# MSPM0G121X register map
Vendor: Texas Instruments; File version: Revised: 2025-10-06 10:58:04
CPU: CM0 r0p1, little endian, MPU, no FPU, 3 interrupt priority bits
Registers are 32-bit, read-write, reset 0x0 unless marked. A register's access mark holds for its fields unless they carry their own. Offsets are from the block's base; [hi:lo] are bit positions; lines under a group give offsets from that group; {n}, {i} and the like mark numbered series; 'fields as' and 'values as' point back to an identical list.

## TIMG8 — PERIPHERALREGION
Base 0x40090000
0x400 TIMG8_FSUB_0 — Subsciber Port 0
  [3:0] CHANID — 0 = disconnected. 1-15 = connected to channelID = CHANID.
    0=UNCONNECTED (A value of 0 specifies that the event is not connected)
0x404 TIMG8_FSUB_1 — Subscriber Port 1
  fields as TIMG8_FSUB_0
0x444 TIMG8_FPUB_0 — Publisher Port 0
  fields as TIMG8_FSUB_0
0x448 TIMG8_FPUB_1 — Publisher Port 1
  fields as TIMG8_FSUB_0
{0x800+0x18*i} TIMG8_GPRCM[{i}] (i=0..0) group
  0x00 TIMG8_PWREN — Power enable
    [0] ENABLE — Enable the power
      0=DISABLE (Disable Power); 1=ENABLE (Enable Power)
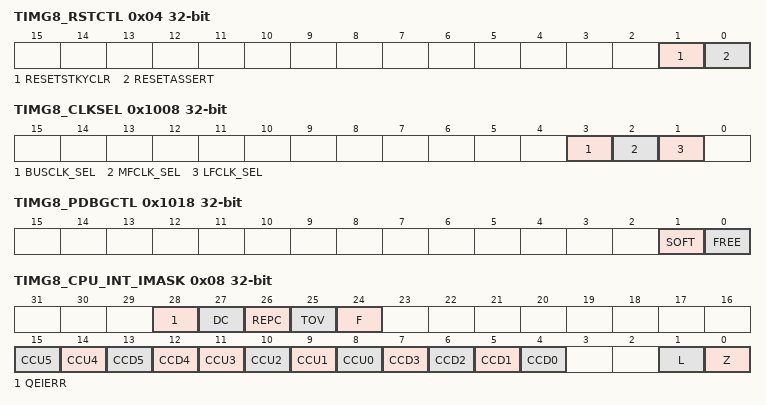
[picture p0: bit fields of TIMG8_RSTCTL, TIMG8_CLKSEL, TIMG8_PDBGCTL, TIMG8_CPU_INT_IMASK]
  0x04 TIMG8_RSTCTL wo — Reset Control
    [1] RESETSTKYCLR — Clear the RESETSTKY bit in the STAT register
      0=NOP (Writing 0 has no effect); 1=CLR (Clear reset sticky bit)
    [0] RESETASSERT — Assert reset to the peripheral
      0=NOP (Writing 0 has no effect); 1=ASSERT (Assert reset)
  0x14 TIMG8_STAT ro — Status Register
    [16] RESETSTKY — This bit indicates, if the peripheral was reset, since this bit was cleared by RESETSTKYCLR in the RSTCTL register
      0=NORES (The peripheral has not been reset since this bit was last cleared by RESETSTKYCLR in the RSTCTL register); 1=RESET (The peripheral was reset since the last bit clear)
0x1000 TIMG8_CLKDIV — Clock Divider
  [2:0] RATIO — Selects divide ratio of module clock
    0=DIV_BY_1 (Do not divide clock source); {v}=DIV_BY_{v+1} (Divide clock source by {v+1}) (v=1..7)
0x1008 TIMG8_CLKSEL — Clock Select for Ultra Low Power peripherals
  [all] fields
    0=DISABLE (Does not select this clock as a source); 1=ENABLE (Select this clock as a source)
  [3] BUSCLK_SEL — Selects BUSCLK as clock source if enabled
  [2] MFCLK_SEL — Selects MFCLK as clock source if enabled
  [1] LFCLK_SEL — Selects LFCLK as clock source if enabled
0x1018 TIMG8_PDBGCTL — Peripheral Debug Control
  [1] SOFT — Soft halt boundary control. This function is only available, if [FREE] is set to 'STOP'
    0=IMMEDIATE (The peripheral will halt immediately, even if the resultant state will result in corruption if the system is restarted); 1=DELAYED (The peripheral blocks the debug freeze until it has reached a boundary where it can resume without corruption)
  [0] FREE — Free run control
    0=STOP (The peripheral freezes functionality while the Core Halted input is asserted and resumes when it is deasserted.); 1=RUN (The peripheral ignores the state of the Core Halted input)
{0x1020+0x2C*i} TIMG8_CPU_INT[{i}] (i=0..0) group
  0x00 TIMG8_CPU_INT_IIDX ro — Interrupt index
    [7:0] STAT — Interrupt index status
      0=NO_INTR (No interrupt pending); 1=Z (Interrupt Source: Zero event (Z)); 2=L (nterrupt Source: Load event (L)); {v}=CCD{v-5} (Interrupt Source: Capture or compare down event (CCD{v-5})) (v=5..8); {v}=CCU{v-9} (Interrupt Source: Capture or compare up event (CCU{v-9})) (v=9..12); 13=CCD4 (Interrupt Source: Compare down event (CCD4)); 14=CCD5 (Interrupt Source: Compare down event (CCD5)); 15=CCU4 (Interrupt Source: Compare down event (CCU4)); 16=CCU5 (Interrupt Source: Compare down event (CCU5)); 25=F (Interrupt Source: Fault Event generated an interrupt. (F)); 26=TOV (Interrupt Source: Trigger overflow (TOV)); 27=REPC (Interrupt Source: Repeat Counter Zero (REPC)); 28=DC (Interrupt Source: Direction Change (DC)); 29=QEIERR (Interrupt Source:QEI Incorrect state transition error (QEIERR))
  0x08 TIMG8_CPU_INT_IMASK — Interrupt mask
    [28] QEIERR — QEIERR Event mask
      0=CLR (Disable Event); 1=SET (Enable Event)
    [27] DC — Direction Change Event mask
      0=CLR (Disable Event); 1=SET (Enable Event)
    [26] REPC — Repeat Counter Zero Event mask
      0=CLR (Disable Event); 1=SET (Enable Event)
    [25] TOV — Trigger Overflow Event mask
      0=CLR (Disable Event); 1=SET (Enable Event)
    [24] F — Fault Event mask
      0=CLR (Disable Event); 1=SET (Enable Event)
    [15] CCU5 — Compare UP event mask CCP5
      0=CLR (Clear Interrupt Mask); 1=SET (Set Interrupt Mask)
    [14] CCU4 — Compare UP event mask CCP4
      0=CLR (Clear Interrupt Mask); 1=SET (Set Interrupt Mask)
    [13] CCD5 — Compare DN event mask CCP5
      0=CLR (Clear Interrupt Mask); 1=SET (Set Interrupt Mask)
    [12] CCD4 — Compare DN event mask CCP4
      0=CLR (Clear Interrupt Mask); 1=SET (Set Interrupt Mask)
    [n+8] CCU{n} (n=0..3) — Capture or Compare UP event mask CCP{n}
      0=CLR (Clear Interrupt Mask); 1=SET (Set Interrupt Mask)
    [n+4] CCD{n} (n=0..3) — Capture or Compare DN event mask CCP{n}
      0=CLR (Clear Interrupt Mask); 1=SET (Set Interrupt Mask)
    [1] L — Load Event mask
      0=CLR (Clear Interrupt Mask); 1=SET (Set Interrupt Mask)
    [0] Z — Zero Event mask
      0=CLR (Disable Event); 1=SET (Enable Event)
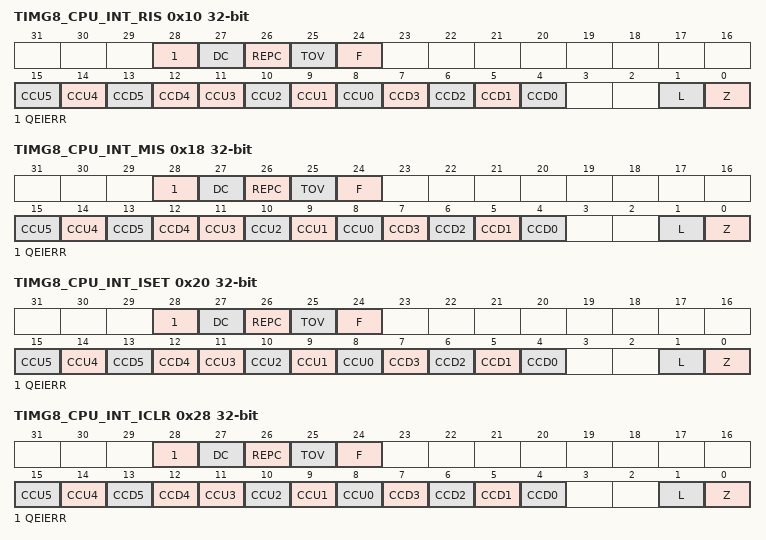
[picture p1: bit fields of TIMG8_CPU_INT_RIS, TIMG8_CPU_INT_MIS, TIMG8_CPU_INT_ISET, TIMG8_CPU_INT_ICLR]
  0x10 TIMG8_CPU_INT_RIS ro — Raw interrupt status
    [all] fields
      0=CLR (Event Cleared); 1=SET (Event Set)
    [28] QEIERR — QEIERR, set on an incorrect state transition on the encoder interface.
    [27] DC — Direction Change
    [26] REPC — Repeat Counter Zero
    [25] TOV — Trigger overflow
    [24] F — Fault
    [15] CCU5 — Compare up event generated an interrupt CCP5
    [14] CCU4 — Compare up event generated an interrupt CCU4
    [13] CCD5 — Compare down event generated an interrupt CCD5
    [12] CCD4 — Compare down event generated an interrupt CCD4
    [n+8] CCU{n} (n=0..3) — Capture or compare up event generated an interrupt CCP{n}
    [n+4] CCD{n} (n=0..3) — Capture or compare down event generated an interrupt CCP{n}
    [1] L — Load event generated an interrupt.
    [0] Z — Zero event generated an interrupt.
  0x18 TIMG8_CPU_INT_MIS ro — Masked interrupt status
    [all] fields
      0=CLR (Event Cleared); 1=SET (Event Set)
    [28] QEIERR
    [27] DC — Direction Change
    [26] REPC — Repeat Counter Zero
    [25] TOV — Trigger overflow
    [24] F — Fault
    [15] CCU5 — Compare up event generated an interrupt CCP5
    [14] CCU4 — Compare up event generated an interrupt CCP4
    [13] CCD5 — Compare down event generated an interrupt CCP5
    [12] CCD4 — Compare down event generated an interrupt CCP4
    [n+8] CCU{n} (n=0..3) — Capture or compare up event generated an interrupt CCP{n}
    [n+4] CCD{n} (n=0..3) — Capture or compare down event generated an interrupt CCP{n}
    [1] L — Load event generated an interrupt.
    [0] Z — Zero event generated an interrupt.
  0x20 TIMG8_CPU_INT_ISET wo — Interrupt set
    [all] fields
      0=NO_EFFECT (Writing 0 has no effect.); 1=SET (Event Set)
    [28] QEIERR — QEIERR event SET
    [27] DC — Direction Change event SET
    [26] REPC — Repeat Counter Zero event SET
    [25] TOV — Trigger Overflow event SET
    [24] F — Fault event SET
    [15] CCU5 — Compare up event 5 SET
    [14] CCU4 — Compare up event 4 SET
    [13] CCD5 — Compare down event 5 SET
    [12] CCD4 — Compare down event 4 SET
    [n+8] CCU{n} (n=0..3) — Capture or compare up event SET
    [n+4] CCD{n} (n=0..3) — Capture or compare down event SET
    [1] L — Load event SET
    [0] Z — Zero event SET
  0x28 TIMG8_CPU_INT_ICLR wo — Interrupt clear
    [all] fields
      0=NO_EFFECT (Writing 0 has no effect.); 1=CLR (Event Clear)
    [28] QEIERR — QEIERR event CLEAR
    [27] DC — Direction Change event CLEAR
    [26] REPC — Repeat Counter Zero event CLEAR
    [25] TOV — Trigger Overflow event CLEAR
    [24] F — Fault event CLEAR
    [15] CCU5 — Compare up event 5 CLEAR
    [14] CCU4 — Compare up event 4 CLEAR
    [13] CCD5 — Compare down event 5 CLEAR
    [12] CCD4 — Compare down event 4 CLEAR
    [n+8] CCU{n} (n=0..3) — Capture or compare up event CLEAR
    [n+4] CCD{n} (n=0..3) — Capture or compare down event CLEAR
    [1] L — Load event CLEAR
    [0] Z — Zero event CLEAR
{0x1050+0x2C*i} TIMG8_GEN_EVENT0[{i}] (i=0..0) group
  0x00 TIMG8_GEN_EVENT0_IIDX ro — Interrupt index
    fields as TIMG8_CPU_INT[0].TIMG8_CPU_INT_IIDX
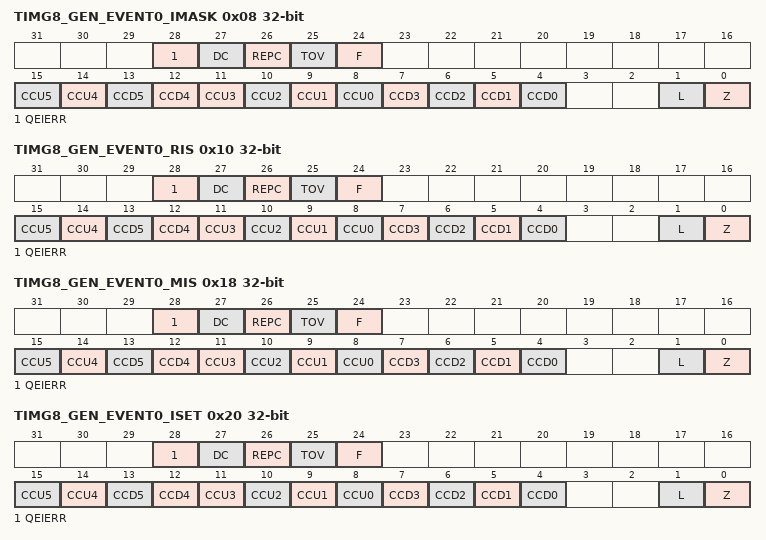
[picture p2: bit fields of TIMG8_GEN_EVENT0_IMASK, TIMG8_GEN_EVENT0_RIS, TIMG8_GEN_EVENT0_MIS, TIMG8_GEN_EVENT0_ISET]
  0x08 TIMG8_GEN_EVENT0_IMASK — Interrupt mask
    fields as TIMG8_CPU_INT[0].TIMG8_CPU_INT_IMASK
  0x10 TIMG8_GEN_EVENT0_RIS ro — Raw interrupt status
    fields as TIMG8_CPU_INT[0].TIMG8_CPU_INT_RIS
  0x18 TIMG8_GEN_EVENT0_MIS ro — Masked interrupt status
    fields as TIMG8_CPU_INT[0].TIMG8_CPU_INT_MIS
  0x20 TIMG8_GEN_EVENT0_ISET wo — Interrupt set
    fields as TIMG8_CPU_INT[0].TIMG8_CPU_INT_ISET
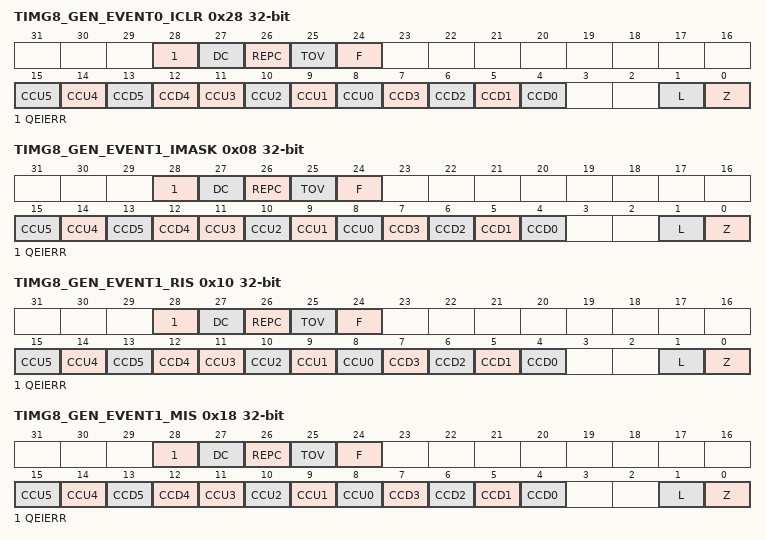
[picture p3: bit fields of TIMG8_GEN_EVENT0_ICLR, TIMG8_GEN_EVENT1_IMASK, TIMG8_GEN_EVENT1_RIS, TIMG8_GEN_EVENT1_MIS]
  0x28 TIMG8_GEN_EVENT0_ICLR wo — Interrupt clear
    fields as TIMG8_CPU_INT[0].TIMG8_CPU_INT_ICLR
{0x1080+0x2C*i} TIMG8_GEN_EVENT1[{i}] (i=0..0) group
  0x00 TIMG8_GEN_EVENT1_IIDX ro — Interrupt index
    fields as TIMG8_CPU_INT[0].TIMG8_CPU_INT_IIDX
  0x08 TIMG8_GEN_EVENT1_IMASK — Interrupt mask
    fields as TIMG8_CPU_INT[0].TIMG8_CPU_INT_IMASK
  0x10 TIMG8_GEN_EVENT1_RIS ro — Raw interrupt status
    fields as TIMG8_CPU_INT[0].TIMG8_CPU_INT_RIS
  0x18 TIMG8_GEN_EVENT1_MIS ro — Masked interrupt status
    fields as TIMG8_CPU_INT[0].TIMG8_CPU_INT_MIS
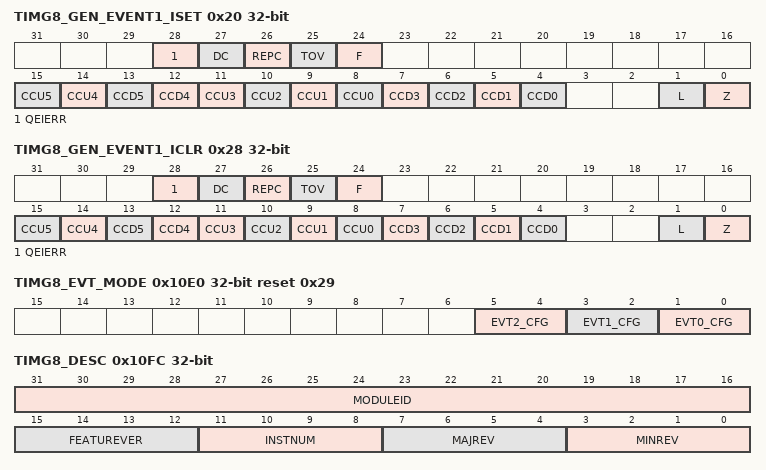
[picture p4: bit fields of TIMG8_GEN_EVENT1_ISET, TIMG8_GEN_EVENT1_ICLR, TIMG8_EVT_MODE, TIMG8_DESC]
  0x20 TIMG8_GEN_EVENT1_ISET wo — Interrupt set
    fields as TIMG8_CPU_INT[0].TIMG8_CPU_INT_ISET
  0x28 TIMG8_GEN_EVENT1_ICLR wo — Interrupt clear
    fields as TIMG8_CPU_INT[0].TIMG8_CPU_INT_ICLR
0x10E0 TIMG8_EVT_MODE reset 0x29 — Event Mode
  [all] fields
    0=DISABLE (The interrupt or event line is disabled.); 1=SOFTWARE (The interrupt or event line is in software mode. Software must clear the RIS.); 2=HARDWARE (The interrupt or event line is in hardware mode. The hardware (another module) clears automatically the associated RIS flag.)
  [5:4] EVT2_CFG ro — Event line mode select for event corresponding to GEN_EVENT1
  [3:2] EVT1_CFG ro — Event line mode select for event corresponding to GEN_EVENT0
  [1:0] EVT0_CFG ro — Event line mode select for event corresponding to CPU_INT
0x10FC TIMG8_DESC ro — Module Description
  [31:16] MODULEID — Module identification contains a unique peripheral identification number. The assignments are maintained in a central database for all of the platform modules to ensure uniqueness.
  [15:12] FEATUREVER — Feature Set for the module *instance*
  [11:8] INSTNUM — Instance Number within the device. This will be a parameter to the RTL for modules that can have multiple instances
  [7:4] MAJREV — Major rev of the IP
  [3:0] MINREV — Minor rev of the IP
{0x1100+0x28*i} TIMG8_COMMONREGS[{i}] (i=0..0) group
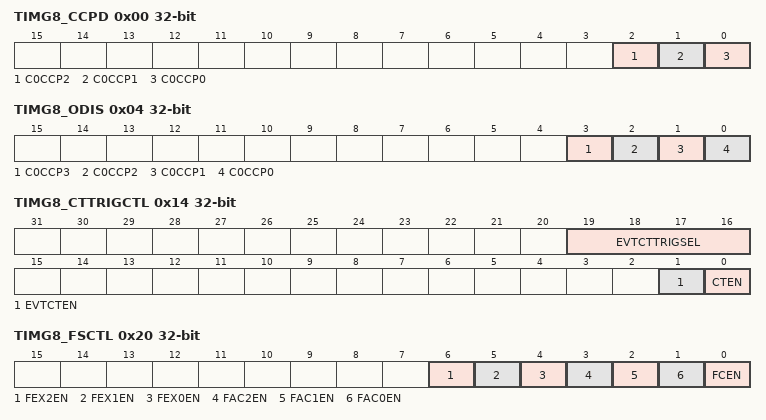
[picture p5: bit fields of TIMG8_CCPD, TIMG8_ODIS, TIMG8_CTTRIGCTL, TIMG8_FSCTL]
  0x00 TIMG8_CCPD — CCP Direction
    [all] fields
      0=INPUT; 1=OUTPUT
    [2] C0CCP2 — CCP2 direction
    [1] C0CCP1 — CCP1 direction
    [0] C0CCP0 — CCP0 direction
  0x04 TIMG8_ODIS — Output Disable
    [3] C0CCP3 — Counter CCP3 Disable Mask Defines whether CCP3 of Counter n is forced low or not
      0=CCP_OUTPUT_OCTL (Output function as selected by the OCTL register CCPO field are provided to occpout[2].); 1=CCP_OUTPUT_LOW (CCP output occpout[3] is forced low.)
    [2] C0CCP2 — Counter CCP2 Disable Mask Defines whether CCP2 of Counter n is forced low or not
      0=CCP_OUTPUT_OCTL (Output function as selected by the OCTL register CCPO field are provided to output inversion block.); 1=CCP_OUTPUT_LOW (CCP output occpout[2] is forced low.)
    [1] C0CCP1 — Counter CCP1 Disable Mask Defines whether CCP0 of Counter n is forced low or not
      0=CCP_OUTPUT_OCTL (Output function as selected by the OCTL register CCPO field are provided to output inversion block.); 1=CCP_OUTPUT_LOW (CCP output occpout[1] is forced low.)
    [0] C0CCP0 — Counter CCP0 Disable Mask Defines whether CCP0 of Counter n is forced low or not
      0=CCP_OUTPUT_OCTL (Output function as selected by the OCTL register CCPO field are provided to output inversion block.); 1=CCP_OUTPUT_LOW (CCP output occpout[0] is forced low.)
  0x08 TIMG8_CCLKCTL — Counter Clock Control Register
    [0] CLKEN — Clock Enable Disables the clock gating to the module. SW has to explicitly program the value to 0 to gate the clock.
      0=DISABLED (Clock is disabled.); 1=ENABLED (Clock is enabled)
  0x0C TIMG8_CPS — Clock Prescale Register
    [7:0] PCNT — Pre-Scale Count This field specifies the pre-scale count value. The selected TIMCLK source is divided by a value of (PCNT+1). A PCNT value of 0 divides TIMCLK by 1, effectively bypassing the divider. A PCNT value of greater than 0 divides the TIMCLK source generating a slower clock
  0x10 TIMG8_CPSV ro — Clock prescale count status register
    [7:0] CPSVAL — Current Prescale Count Value
  0x14 TIMG8_CTTRIGCTL — Timer Cross Trigger Control Register
    [19:16] EVTCTTRIGSEL — Used to Select the subscriber port that should be used for input cross trigger.
      0=FSUB0 (Use FSUB0 as cross trigger source.); 1=FSUB1 (Use FSUB1 as cross trigger source.); 2=Z (Use Zero event as cross trigger source.); 3=L (Use Load event as cross trigger source.); {v}=CCD{v-4} (Use CCD{v-4} event as cross trigger source.) (v=4..7); {v}=CCU{v-8} (Use CCU{v-8} event as cross trigger source.) (v=8..11)
    [1] EVTCTEN — Enable the Input Trigger Conditions to the Timer module as a condition for Cross Triggers.
      0=DISABLED (Cross trigger generation disabled.); 1=ENABLE (Cross trigger generation enabled)
    [0] CTEN — Timer Cross trigger enable. This field is used to enable whether the SW or HW logic can generate a timer cross trigger event in the system. These cross triggers are connected to the respective timer trigger in of the other timer IPs in the SOC power domain. The timer cross trigger is essentially the combined logic of the HW and SW conditions controlling EN bit in the CTRCTL register.
      values as EVTCTEN
  0x1C TIMG8_CTTRIG wo — Timer Cross Trigger Register
    [0] TRIG — Generate Cross Trigger This bit when programmed will generate a synchronized trigger condition all the cross trigger enabled Timer instances including current timer instance.
      0=DISABLED (Cross trigger generation disabled); 1=GENERATE (Generate Cross trigger pulse)
  0x20 TIMG8_FSCTL — Fault Source Control
    [all] fields
      0=DISABLE; 1=ENABLE
    [6] FEX2EN — This field controls whether the fault is caused by external fault pin 2.
    [5] FEX1EN — This field controls whether the fault is caused by external fault pin 1.
    [4] FEX0EN — This field controls whether the fault is caused by external fault pin 0.
    [3] FAC2EN — This field controls whether the fault is caused by COMP2 output.
    [2] FAC1EN — This field controls whether the fault is caused by COMP1 output.
    [1] FAC0EN — This field controls whether the fault signal is caused by COMP0 output.
    [0] FCEN — This field controls whether the fault is caused by the system clock fault.
  0x24 TIMG8_GCTL — Global control register
    [0] SHDWLDEN — Enables shadow to active load of bufferred registers and register fields.
      0=DISABLE; 1=ENABLE
{0x1800+0xD8*i} TIMG8_COUNTERREGS[{i}] (i=0..0) group
  0x00 TIMG8_CTR — Counter Register
    [31:0] CCTR — Current Counter value
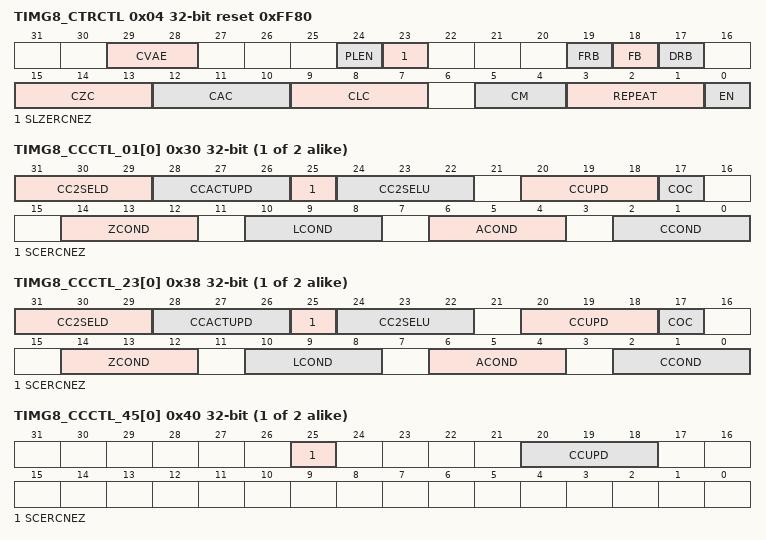
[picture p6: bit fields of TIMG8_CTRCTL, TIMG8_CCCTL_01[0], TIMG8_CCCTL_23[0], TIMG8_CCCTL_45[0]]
  0x04 TIMG8_CTRCTL reset 0xFF80 — Counter Control Register
    [29:28] CVAE — Counter Value After Enable. This field specifies the initialization condition of the counter when the EN bit is changed from 0 to 1 by a write to the CTRCTL register. Note that an external event can also cause the EN bit to go active.
      0=LDVAL (The counter is set to the LOAD register value); 1=NOCHANGE (The counter value is unchanged from its current value which could have been initialized by software); 2=ZEROVAL (The counter is set to zero)
    [24] PLEN — Phase Load Enable. This bit allows the timer to have phase load feature.
      0=DISABLED; 1=ENABLED
    [23] SLZERCNEZ — Suppress Load and Zero Events if Repeat Counter is Not Equal to Zero. This bit suppresses the generation of the Z (zero) and L (load) events from the counter when the repeat counter (RC) value is not 0.
      0=DISABLED (Disabled. Z and L events are always generated from the counter when their conditions are generated.); 1=ENABLED (Enabled. Z and L events are generated from the counter when their conditions are generated and the RC register value is 0.)
    [19] FRB — Fault Resume Behavior This bit specifies what the device does following the release/exit of fault condition.
      0=RESUME (Resume counting); 1=CVAE_ACTION (Perform the action as specified by the CVAE field.)
    [18] FB — Fault Behavior This bit specifies whether the counter continues running or suspends during a fault mode. There is a separate control under REPEAT to indicate whether counting is to suspend at next Counter==0
      0=CONT_COUNT (Continues counting); 1=SUSP_COUNT (Suspends counting)
    [17] DRB — Debug Resume Behavior This bit specifies what the device does following the release/exit of debug mode.
      values as FRB
    [15:13] CZC — Counter Zero Control This field specifies what controls the counter operation with respect to zeroing the counter value. Encodings 1-3 are present based on the CCPC parameter value. Bits 4-5 are present based on the HQEI parameter value. Any encodings not provided are documented as reserved.
      0=CCCTL0_ZCOND; 1=CCCTL1_ZCOND; 2=CCCTL2_ZCOND (CCCTL_2 ZCOND This value exists when there are 4 channels.); 3=CCCTL3_ZCOND (CCCTL_3 ZCOND This value exists when there are 4 channels.); 4=QEI_2INP (Controlled by 2-input QEI mode This value exists when TIMER support QEI feature.); 5=QEI_3INP (Controlled by 3-input QEI mode This value exists when TIMER support QEI feature.)
    [12:10] CAC — Counter Advance Control. This field specifies what controls the counter operation with respect to advancing (incrementing or decrementing) the counter value. Encodings 1-3 are present based on the CCPC parameter value. Bits 4-5 are present based on the HQEI parameter value. Any encodings not provided are documented as reserved.
      0=CCCTL0_ACOND; 1=CCCTL1_ACOND; 2=CCCTL2_ACOND (CCCTL_2 ACOND This value exists when there are 4 channels.); 3=CCCTL3_ACOND (CCCTL_3 ACOND This value exists when there are 4 channels.); 4=QEI_2INP (Controlled by 2-input QEI mode This value exists when TIMER support QEI feature.); 5=QEI_3INP (Controlled by 3-input QEI mode This value exists when TIMER support QEI feature.)
    [9:7] CLC — Counter Load Control. This field specifies what controls the counter operation with respect to setting the counter to the LD register value. Encodings 1-3 are present based on the CCPC parameter value. Bits 4-5 are present based on the HQEI parameter value. Any encodings not provided are documented as reserved.
      0=CCCTL0_LCOND; 1=CCCTL1_LCOND; 2=CCCTL2_LCOND (CCCTL_2 LCOND This value exists when there are 4 channels.); 3=CCCTL3_LCOND (CCCTL_3 LCOND This value exists when there are 4 channels.); 4=QEI_2INP (Controlled by 2 input QEI mode. This value exists when TIMER support QEI feature.); 5=QEI_3INP (Controlled by 3 input QEI mode. This value exists when TIMER support QEI feature.)
    [5:4] CM — Count Mode
      0=DOWN; 1=UP_DOWN; 2=UP (Counter counts up.)
    [3:1] REPEAT — Repeat. The repeat bit controls whether the counter continues to advance following a zero event, or the exiting of a debug or fault condition. If counting down, a zero event is followed by a load at the next advance condition. If counting up-down, a zero event is followed by an advance event (+1). The intent of encoding 3 is that if the debug condition is in effect, the generation of the load pulse is deferred until the debug condition is over. This allows the counter to reach zero before counting is suspended.
      0=Does not automatically advance following a zero event; 1=Continues to advance following a zero event; 3=Continues to advance following a zero event if the debug mode is not in effect, or following the release of the debug mode
    [0] EN — Counter Enable. This bit allows the timer to advance This bit is automatically cleared if REPEAT=0 (do not automatically reload) and the counter value equals zero. CPU Write: A register write that sets the EN bit, the counter value is set per the CVAE value. Hardware: This bit may also be set as the result of an LCOND or ZCOND condition being met and the counter value changed to the load value or zero value, respectively.
      0=DISABLED; 1=ENABLED
  0x08 TIMG8_LOAD — Load Register
    [31:0] LD — Load Value
  {0x10+4j} TIMG8_CC_01[{j}] (j=0..1) — Capture or Compare Register 0/1
    [31:0] CCVAL — Capture or compare value
  {0x18+4j} TIMG8_CC_23[{j}] (j=0..1) — Capture or Compare Register 2/3
    [31:0] CCVAL — Capture or compare value
  {0x20+4j} TIMG8_CC_45[{j}] (j=0..1) — The CC_45 register are a registers which can be used as compare to the current CTR to create an events CC4U, CC4D, CC5U and CC5D.
    [31:0] CCVAL — Capture or compare value
  {0x30+4j} TIMG8_CCCTL_01[{j}] (j=0..1) — Capture or Compare Control Registers 0/1
    [31:29] CC2SELD — Selects the source second CCD event.
      {v}=SEL_CCD{v} (Selects CCD from CC{v}.) (v=0..5)
    [28:26] CCACTUPD — CCACT shadow register Update Method This field controls how updates to the CCACT shadow register are performed
      0=Immediately (Value written to the CCACT register has immediate effect.); 1=Zero_EVT (Following a zero event (CTR=0) Writes to the CCACTx_y register are stored in shadow register and transferred to CCACTx_y in the TIMCLK cycle following CTR equals 0.); 2=Compare_Down_EVT (Following a CCD event (CTR=CC_xy) Writes to the CCACTx_y register are stored in shadow register and transferred to CCACTx_y in the TIMCLK cycle following CTR equals the CCx_y register value.); 3=Compare_UP_EVT (Following a CCU event (CTR=CC_xy) Writes to the CCACTx_y register are stored in shadow register and transferred to CCACTx_y in the TIMCLK cycle following CTR equals the CCx_y register value.); 4=ZERO_LOAD_EVT (Following a zero event (CTR=0) or load event (CTR = LOAD) Writes to the CCACTx_y register are stored in shadow register and transferred to CCACTx_y in the TIMCLK cycle following CTR equals 0 or CTR. Equals LDn. Note this update mechanism is defined for use only in configurations using up/down counting. This mode is not intended for use in down count configurations.); 5=ZERO_RC_ZERO_EVT (Following a zero event (CTR=0) with repeat count also zero (RC=0). Writes to the CCACTx_y register are stored in shadow register and transferred to CCACTx_y in the TIMCLK cycle following CTR equals 0 and if RC equal 0.); 6=TRIG (On a TRIG pulse, the value stored in CCACT_xy shadow register is loaded into CCACT_xy register.)
    [25] SCERCNEZ — Suppress Compare Event if Repeat Counter is Not Equal to Zero This bit suppresses the generation of the compare (CCD, CCU and RC) events from the counter when the repeat counter (RC) value is not 0.
      0=DISABLED (CCD, CCU and RC events are always generated from the counter when their conditions are generated.); 1=ENABLED (CCD, CCU and RC events are generated from the counter when their conditions are generated and the RC register value is 0.)
    [24:22] CC2SELU — Selects the source second CCU event.
      {v}=SEL_CCU{v} (Selects CCU from CC{v}.) (v=0..5)
    [20:18] CCUPD — Capture and Compare Update Method This field controls how updates to the shadow capture and compare register are performed (when operating in compare mode, COC=0).
      0=Immediately (Writes to the CCx_y register is written to the register directly and has immediate effect.); 1=Zero_EVT (Following a zero event (CTR=0) Writes to the CCx_y register are stored in shadow register and transferred to CCx_y in the TIMCLK cycle following CTR equals 0.); 2=Compare_Down_EVT (Following a CCD event (CTR=CC_xy) Writes to the CCx_y register are stored in shadow register and transferred to CCx_y in the TIMCLK cycle following CTR equals the CCx_y register value.); 3=Compare_UP_EVT (Following a CCU event (CTR=CC_xy) Writes to the CCx_y register are stored in shadow register and transferred to CCx_y in the TIMCLK cycle following CTR equals the CCx_y register value.); 4=ZERO_LOAD_EVT (Following a zero event(CTR=0) or load event (CTR=LOAD) Writes to the CCx_y register are stored in shadow register and transferred to ECCx_y in the TIMCLK cycle following CTR equals 0 or CTR. Equals LD. Note this update mechanism is defined for use only in configurations using up/down counting. This mode is not intended for use in down count configurations.); 5=ZERO_RC_ZERO_EVT (Following a zero event (CTR=0) with repeat count also zero (RC=0). Writes to the CCx_y register are stored in shadow register and transferred to CCx_y in the TIMCLK cycle following CTR equals 0 and if RC equal 0.); 6=TRIG (Following a TRIG pulse. Writes to the CCx_y register are stored in shadow register and transferred to CCx_y)
    [17] COC — Capture or Compare. #br# Specifies whether the corresponding CC register is used as a capture register or a compare register (never both).
      0=COMPARE; 1=CAPTURE
    [14:12] ZCOND — Zero Condition. #br# This field specifies the condition that generates a zero pulse.
      0=CC_TRIG_NO_EFFECT (CCP edges have no effect); 1=CC_TRIG_RISE (Rising edge of CCP or trigger assertion edge); 2=CC_TRIG_FALL (Falling edge of CCP or trigger de-assertion edge); 3=CC_TRIG_EDGE (Either edge of CCP or trigger change (assertion/de-assertion edge))
    [10:8] LCOND — Load Condition. #br# Specifies the condition that generates a load pulse.
      values as ZCOND
    [6:4] ACOND — Advance Condition. #br# Specifies the condition that generates an advance pulse.
      0=TIMCLK (Each TIMCLK); 1=CC_TRIG_RISE (Rising edge of CCP or trigger assertion edge); 2=CC_TRIG_FALL (Falling edge of CCP or trigger de-assertion edge); 3=CC_TRIG_EDGE (Either edge of CCP or trigger change (assertion/de-assertion edge)); 5=CC_TRIG_HIGH (CCP High or Trigger assertion (level))
    [2:0] CCOND — Capture Condition. #br# Specifies the condition that generates a capture pulse.
      0=NOCAPTURE (None (never captures)); 1=CC_TRIG_RISE (Rising edge of CCP or trigger assertion edge); 2=CC_TRIG_FALL (Falling edge of CCP or trigger de-assertion edge); 3=CC_TRIG_EDGE (Either edge of CCP or trigger change (assertion/de-assertion edge))
  {0x38+4j} TIMG8_CCCTL_23[{j}] (j=0..1) — Capture or Compare Control Registers 2/3
    [31:29] CC2SELD — Selects the source second CCD event.
      {v}=SEL_CCD{v} (Selects CCD from CC{v}.) (v=0..5)
    [28:26] CCACTUPD — CCACT shadow register Update Method This field controls how updates to the CCCACT shadow register are performed
      0=Immediately (Value written to the CCACTx_y register has immediate effect.); 1=Zero_EVT (Following a zero event (CTR=0) Writes to the CCACTx_y register are stored in shadow register and transferred to CCACTx_y in the TIMCLK cycle following CTR equals 0.); 2=Compare_Down_EVT (Following a CCD event (CTR=CC_xy) Writes to the CCACTx_y register are stored in shadow register and transferred to CCACTx_y in the TIMCLK cycle following CTR equals the CCx_y register value.); 3=Compare_UP_EVT (Following a CCU event (CTR=cc_xy) Writes to the CCACTx_y register are stored in shadow register and transferred to CCACTx_y in the TIMCLK cycle following CTR equals the CCx_y register value.); 4=ZERO_LOAD_EVT (Following a zero event (CTR=0) or load event (CTR=LOAD) Writes to the CCACTx_y register are stored in shadow register and transferred to CCACTx_y in the TIMCLK cycle following CTR equals 0 or CTR. Equals LDn. Note this update mechanism is defined for use only in configurations using up/down counting. This mode is not intended for use in down count configurations.); 5=ZERO_RC_ZERO_EVT (Following a zero event (CTR=0) with repeat count also zero (RC=0). Writes to the CCACTx_y register are stored in shadow register and transferred to CCACTx_y in the TIMCLK cycle following CTR equals 0 and if RC equal 0.); 6=TRIG (On a TRIG pulse, the value stored in CCACTx_y shadow register is loaded into CCACTx_y active register.)
    [25] SCERCNEZ — Suppress Compare Event if Repeat Counter is Not Equal to Zero This bit suppresses the generation of the compare (CCD, CCU and RC) events from the counter when the repeat counter (RCn) value is not 0.
      values as TIMG8_COUNTERREGS[0].TIMG8_CCCTL_01[0].SCERCNEZ
    [24:22] CC2SELU — Selects the source second CCU event.
      {v}=SEL_CCU{v} (Selects CCU from CC{v}.) (v=0..5)
    [20:18] CCUPD — Capture and Compare Update Method This field controls how updates to the shadow capture and compare register are performed (when operating in compare mode, COC=0).
      0=Immediately (Writes to the CCx_y register is written to the register directly and has immediate effect.); 1=Zero_EVT (Following a zero event (CTR=0) Writes to the CCx_y register are stored in shadow register and transferred to CCx_y in the TIMCLK cycle following CTR equals 0.); 2=Compare_Down_EVT (Following a CCD event (CTR=CC_xy) Writes to the CCx_y register are stored in shadow register and transferred to CCx_y in the TIMCLK cycle following CTR equals the CCx_y register value.); 3=Compare_UP_EVT (Following a CCU event (CTR=CC_xy) Writes to the CCx_y register are stored in shadow register and transferred to CCx_y in the TIMCLK cycle following CTR equals the CCx_y register value.); 4=ZERO_LOAD_EVT (Following a zero or load event Writes to the CCx_y register are stored in shadow register and transferred to CCx_y in the TIMCLK cycle following CTR equals 0 or CTR. Equals LDn. Note this update mechanism is defined for use only in configurations using up/down counting. This mode is not intended for use in down count configurations.); 5=ZERO_RC_ZERO_EVT (Following a zero event (CTR=0) with repeat count also zero (RC=0). Writes to the CCx_y register are stored in shadow register and transferred to CCx_y in the TIMCLK cycle following CTR equals 0 and if RC equal 0.); 6=TRIG (Following a TRIG pulse. Writes to the CCx_y register are stored in shadow register and transferred to CCx_y #xD; 0.)
    [17] COC — Capture or Compare. #br# Specifies whether the corresponding CC register is used as a capture register or a compare register (never both).
      0=COMPARE; 1=CAPTURE
    [14:12] ZCOND — Zero Condition. #br# This field specifies the condition that generates a zero pulse. 4h-Fh = Reserved
      values as TIMG8_COUNTERREGS[0].TIMG8_CCCTL_01[0].ZCOND
    [10:8] LCOND — Load Condition. #br# Specifies the condition that generates a load pulse. 4h-Fh = Reserved
      values as TIMG8_COUNTERREGS[0].TIMG8_CCCTL_01[0].ZCOND
    [6:4] ACOND — Advance Condition. #br# Specifies the condition that generates an advance pulse. 6h-Fh = Reserved
      values as TIMG8_COUNTERREGS[0].TIMG8_CCCTL_01[0].ACOND
    [2:0] CCOND — Capture Condition. #br# Specifies the condition that generates a capture pulse. 4h-Fh = Reserved
      values as TIMG8_COUNTERREGS[0].TIMG8_CCCTL_01[0].CCOND
  {0x40+4j} TIMG8_CCCTL_45[{j}] (j=0..1) — Capture or Compare Control Registers 4/5
    [25] SCERCNEZ — Suppress Compare Event if Repeat Counter is Not Equal to Zero This bit suppresses the generation of the compare (CCD, CCU and RC) events from the counter when the repeat counter (RC) value is not 0.
      values as TIMG8_COUNTERREGS[0].TIMG8_CCCTL_01[0].SCERCNEZ
    [20:18] CCUPD — Capture and Compare Update Method This field controls how updates to the shadow capture and compare register are performed (when operating in compare mode, COC=0).
      0=Immediately (Writes to the CCx_y register is written to the register directly and has immediate effect.); 1=Zero_EVT (Following a zero event (CTR=0) Writes to the CCx_y register are stored in shadow register and transferred to ECCx_y in the TIMCLK cycle following CTR equals 0.); 2=Compare_Down_EVT (Following a CCD event (CTR=CC_xy) Writes to the CCx_y register are stored in shadow register and transferred to CCx_y in the TIMCLK cycle following CTR equals the CCx_y register value.); 3=Compare_UP_EVT (Following a CCU event (CTR=CC_xy) Writes to the CCx_y register are stored in shadow register and transferred to CCx_y in the TIMCLK cycle following CTR equals the CCx_y register value.); 4=ZERO_LOAD_EVT (Following a zero event (CTR=0) or load event (CTR=LOAD) Writes to the CCx_y register are stored in shadow register and transferred to CCx_y in the TIMCLK cycle following CTR equals 0 or CTR. Equals LD. Note this update mechanism is defined for use only in configurations using up/down counting. This mode is not intended for use in down count configurations.); 5=ZERO_RC_ZERO_EVT (Following a zero event (CTR=0) with repeat count also zero (RC=0). Writes to the CCx_y register are stored in shadow register and transferred to CCx_y in the TIMCLK cycle following CTR equals 0 and if RC equal 0.); 6=TRIG (Following a TRIG pulse. Writes to the CCx_y register are stored in shadow register and transferred to CCx_y #xD; 0.)
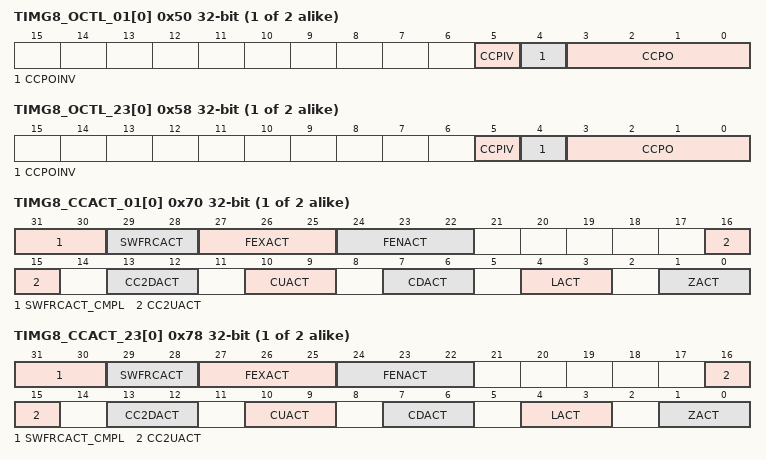
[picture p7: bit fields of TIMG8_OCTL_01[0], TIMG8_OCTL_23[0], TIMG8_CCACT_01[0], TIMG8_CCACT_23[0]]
  {0x50+4j} TIMG8_OCTL_01[{j}] (j=0..1) — CCP Output Control Registers 0/1
    [5] CCPIV — CCP Initial Value This bit specifies the logical value put on the signal generator state while the counter is disabled (CTRCTL.EN == 0).
      0=LOW; 1=HIGH
    [4] CCPOINV — CCP Output Invert The output as selected by CCPO is conditionally inverted.
      0=NOINV (No inversion); 1=INV (Invert)
    [3:0] CCPO — CCP Output Source
      0=FUNCVAL (Signal generator value (for example, PWM, triggered PWM)); 1=LOAD (Load event); 2=CMPVAL (CCU event or CCD event); 4=ZERO (Zero event); 5=CAPCOND (Capture event); 6=FAULTCOND (Fault condition); 8=CC0_MIRROR_ALL (Mirror CCP of first capture and compare register to other capture compare blocks); 9=CC1_MIRROR_ALL (Mirror CCP of second capture and compare register in other capture compare blocks); 12=DEADBAND (Signal generator output after deadband insertion); 13=CNTDIR (Counter direction)
  {0x58+4j} TIMG8_OCTL_23[{j}] (j=0..1) — CCP Output Control Registers 2/3
    [5] CCPIV — CCP Initial Value This bit specifies the logical value put on the signal generator state while the counter is disabled (CTRCTL.EN == 0).
      0=LOW; 1=HIGH
    [4] CCPOINV — CCP Output Invert The output as selected by CCPO is conditionally inverted.
      0=NOINV (No inversion); 1=INV (Invert)
    [3:0] CCPO — CCP Output Source
      0=FUNCVAL (Signal generator value (for example, PWM, triggered PWM)); 1=LOAD (Load condition); 2=CMPVAL (CCU event or CCD event); 4=ZERO (Zero event); 5=CAPCOND (Capture event); 6=FAULTCOND (Fault Condition); 8=CC0_MIRROR_ALL (Mirror CCP of first capture and compare register in other capture compare blocks); 9=CC1_MIRROR_ALL (Mirror CCP of second capture and compare register in other capture compare blocksi /bn,.); 12=DEADBAND (Deadband Inserted Output); 13=CNTDIR (Counter direction)
  {0x70+4j} TIMG8_CCACT_01[{j}] (j=0..1) — Capture or Compare Action Registers 0/1
    [31:30] SWFRCACT_CMPL — CCP Complimentary output Action on Software Force Output This field describes the resulting action of software force. This action has a shadow register, which will be updated under specific condition. So that this register cannot take into effect immediately.
      0=DISABLED (This event is disabled and a lower priority event is selected if asserting. The CCP output value is unaffected by the event.); 1=CCP_HIGH (CCP Complimentary output value is set high); 2=CCP_LOW (CCP Complimentary output value is set low)
    [29:28] SWFRCACT — CCP Output Action on Software Force Output This field describes the resulting action of software force. This action has a shadow register, which will be updated under specific condition. So that this register cannot take into effect immediately.
      0=DISABLED (This event is disabled and a lower priority event is selected if asserting. The CCP output value is unaffected by the event.); 1=CCP_HIGH (CCP output value is set high); 2=CCP_LOW (CCP output value is set low)
    [27:25] FEXACT — CCP Output Action on Fault Exit This field describes the resulting action of the signal generator upon exiting the fault condition.
      0=DISABLED (This event is disabled and a lower priority event is selected if asserting. The CCP output value is unaffected by the event.); 1=CCP_HIGH (CCP output value is set high); 2=CCP_LOW (CCP output value is set low); 3=CCP_TOGGLE (CCP output value is toggled); 4=CCP_HIGHZ (CCP output value is tristated)
    [24:22] FENACT — CCP Output Action on Fault Entry This field describes the resulting action of the signal generator upon detecting a fault.
      values as FEXACT
    [16:15] CC2UACT — CCP Output Action on CC2U event.
      0=DISABLED (This event is disabled and a lower priority event is selected if asserting. The CCP output value is unaffected by the event.); 1=CCP_HIGH (CCP output value is set high); 2=CCP_LOW (CCP output value is set low); 3=CCP_TOGGLE (CCP output value is toggled)
    [13:12] CC2DACT — CCP Output Action on CC2D event.
      values as CC2UACT
    [10:9] CUACT — CCP Output Action on Compare (Up) This field describes the resulting action of the signal generator upon detecting a compare event while counting up.
      values as CC2UACT
    [7:6] CDACT — CCP Output Action on Compare (Down) This field describes the resulting action of the signal generator upon detecting a compare event while counting down.
      values as CC2UACT
    [4:3] LACT — CCP Output Action on Load Specifies what changes occur to CCP output as the result of a load event.
      values as CC2UACT
    [1:0] ZACT — CCP Output Action on Zero Specifies what changes occur to CCP output as the result of a zero event.
      values as CC2UACT
  {0x78+4j} TIMG8_CCACT_23[{j}] (j=0..1) — Capture or Compare Action Registers 2/3
    [31:30] SWFRCACT_CMPL — CCP Complimentary Output Action on Software Force Output This field describes the resulting action of software force. This action has a shadow register, which will be updated under specific condition. So that this register cannot take into effect immediately.
      values as TIMG8_COUNTERREGS[0].TIMG8_CCACT_01[0].SWFRCACT_CMPL
    [29:28] SWFRCACT — CCP Output Action on Software Force Output This field describes the resulting action of software force. This action has a shadow register, which will be updated under specific condition. So that this register cannot take into effect immediately.
      values as TIMG8_COUNTERREGS[0].TIMG8_CCACT_01[0].SWFRCACT
    [27:25] FEXACT — CCP Output Action on Fault Exit This field describes the resulting action of the signal generator upon exiting the fault condition.
      values as TIMG8_COUNTERREGS[0].TIMG8_CCACT_01[0].FEXACT
    [24:22] FENACT — CCP Output Action on Fault Entry This field describes the resulting action of the signal generator upon detecting a fault.
      values as TIMG8_COUNTERREGS[0].TIMG8_CCACT_01[0].FEXACT
    [16:15] CC2UACT — CCP Output Action on CC2U event.
      values as TIMG8_COUNTERREGS[0].TIMG8_CCACT_01[0].CC2UACT
    [13:12] CC2DACT — CCP Output Action on CC2D event.
      values as TIMG8_COUNTERREGS[0].TIMG8_CCACT_01[0].CC2UACT
    [10:9] CUACT — CCP Output Action on Compare (Up) This field describes the resulting action of the signal generator upon detecting a compare event while counting up.
      values as TIMG8_COUNTERREGS[0].TIMG8_CCACT_01[0].CC2UACT
    [7:6] CDACT — CCP Output Action on Compare (Down) This field describes the resulting action of the signal generator upon detecting a compare event while counting down.
      values as TIMG8_COUNTERREGS[0].TIMG8_CCACT_01[0].CC2UACT
    [4:3] LACT — CCP Output Action on Load Specifies what changes occur to CCP output as the result of a load event.
      values as TIMG8_COUNTERREGS[0].TIMG8_CCACT_01[0].CC2UACT
    [1:0] ZACT — CCP Output Action on Zero Specifies what changes occur to CCP output as the result of a zero event.
      values as TIMG8_COUNTERREGS[0].TIMG8_CCACT_01[0].CC2UACT
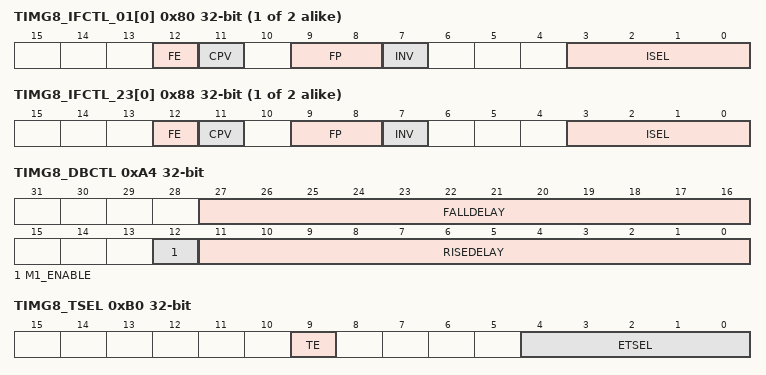
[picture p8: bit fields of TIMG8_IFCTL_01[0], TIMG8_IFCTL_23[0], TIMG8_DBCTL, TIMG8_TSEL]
  {0x80+4j} TIMG8_IFCTL_01[{j}] (j=0..1) — Input Filter Control Register 0/1
    [12] FE — Filter Enable This bit controls whether the input is filtered by the input filter or bypasses to the edge detect.
      0=DISABLED (Bypass.); 1=ENABLED (Filtered.)
    [11] CPV — Consecutive Period/Voting Select This bit controls whether the input filter uses a stricter consecutive period count or majority voting.
      0=Consecutive Periods The input must be at a specific logic level for the period defined by FP before it is passed to the filter output; 1=Voting The filter ignores one clock of opposite logic over the filter period. I.e. Over FP samples of the input, up to 1 sample may be of an opposite logic value (glitch) without affecting the output.
    [9:8] FP — Filter Period. This field specifies the sample period for the input filter. I.e. The input is sampled for FP timer clocks during filtering.
      0=The division factor is 3; 1=The division factor is 5; 2=The division factor is 8
    [7] INV — Input Inversion This bit controls whether the selected input is inverted.
      0=NOINVERT (Noninverted); 1=INVERT (Inverted)
    [3:0] ISEL — Input Select (CCP0) This field selects the input source to the filter input. 4h-7h = Reserved
      0=CCPX_INPUT (CCP of the corresponding capture compare unit); 1=CCPX_INPUT_PAIR (Input pair CCPX of the capture compare unit. For CCP0 input pair is CCP1 and for CCP1 input pair is CCP0.); 2=CCP0_INPUT (CCP0 of the counter); 3=TRIG_INPUT (Trigger); 4=CCP_XOR (XOR of CCP inputs as input source (Used in Hall input mode).); 5=FSUB0 (subscriber 0 event as input source.); 6=FSUB1 (subscriber 1 event as input source.); 7=COMP0 (Comparator 0 output.); 8=COMP1 (Comparator 1 output.); 9=COMP2 (Comparator 2 output.)
  {0x88+4j} TIMG8_IFCTL_23[{j}] (j=0..1) — Input Filter Control Register 2/3
    fields as TIMG8_COUNTERREGS[0].TIMG8_IFCTL_01[0]
  0xA0 TIMG8_PL — Phase Load Register
    [31:0] PHASE — Phase Load value
  0xA4 TIMG8_DBCTL — Dead Band insertion control register
    [27:16] FALLDELAY — Fall Delay The number of TIMCLK periods inserted between the fall edge of CCP signal and the rise edge of CCP complimentary signal.
    [12] M1_ENABLE — Dead Band Mode 1 Enable.
      0=DISABLED; 1=ENABLED
    [11:0] RISEDELAY — Rise Delay The number of TIMCLK periods inserted between the fall edge of CCP signal and the rise edge of CCP complimentary signal.
  0xB0 TIMG8_TSEL — Trigger Select Register
    [9] TE — Trigger Enable. This selects whether a trigger is enabled or not for this counter 0x0 = Triggers are not used 0x1 = Triggers are used as selected by the ETSEL field
      0=DISABLED (Triggers are not used.); 1=ENABLED (Triggers are used as selected by the IE, ITSEL and ETSEL fields.)
    [4:0] ETSEL — External Trigger Select. #br# This selects which System Event is used if the input filter selects trigger. Triggers 0-15 are used to connect triggers generated by other timer modules. Refer to the SoC datasheet for details related to timer trigger sources. Triggers 16 and 17 are connected to event manager subscriber ports. Event lines 18-31 are reserved for future use.
      {v}=TRIG{v} (TRIGx = External trigger input from TIM x.) (v=0..15); 16=TRIG_SUB0 (TRIG_SUBx = External trigger input from subscriber port x.); 17=TRIG_SUB1 (TRIG_SUBx = External trigger input from subscriber port x.)
  0xB4 TIMG8_RC ro — Repeat counter Register
    [7:0] RC — Repeat Counter Value
  0xB8 TIMG8_RCLD — Repeat counter load Register
    [7:0] RCLD — Repeat Counter Load Value This field provides the value loaded into the repeat counter at a load event following the repeat counter value equaling 0.
  0xBC TIMG8_QDIR ro — QEI Count Direction Register
    [0] DIR — Direction of count
      0=DOWN (Down (Phase B leads Phase A)); 1=UP (Up (Phase A leads Phase B))
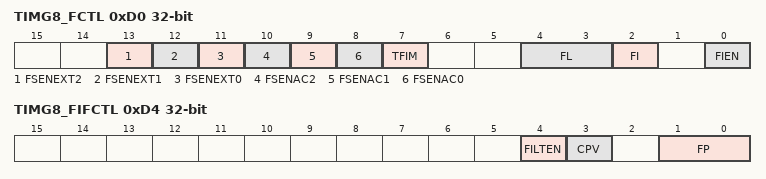
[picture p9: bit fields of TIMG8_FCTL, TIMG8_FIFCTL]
  0xD0 TIMG8_FCTL — Fault Control Register
    [13] FSENEXT2 — Specifies whether the external fault pin2 high/low is treated as fault condition.
      0=LOWCTIVE (Fault Input is active low.); 1=HIGHACTIVE (Fault Input is active high.)
    [12] FSENEXT1 — Specifies whether the external fault pin1 high/low is treated as fault condition.
      values as FSENEXT2
    [11] FSENEXT0 — Specifies whether the external fault pin0 high/low is treated as fault condition.
      values as FSENEXT2
    [10] FSENAC2 — Specifies whether the COMP2 output high/low is treated as fault condition.
      values as FSENEXT2
    [9] FSENAC1 — Specifies whether the COMP1 output high/low is treated as fault condition.
      values as FSENEXT2
    [8] FSENAC0 — Specifies whether the COMP0 output high/low is treated as fault condition.
      values as FSENEXT2
    [7] TFIM — Trigger Fault Input Mask Specifies whether the selected trigger participates as a fault input. If enabled and the trigger asserts, the trigger is treated as a fault.
      0=DISABLED (Selected trigger does not participate in fault condition generation); 1=ENABLED (Selected trigger participates in fault condition generation)
    [4:3] FL — Fault Latch mode Specifies whether the fault condition is latched and configures the latch clear conditions.
      0=NO_LATCH (Overall fault condition is not dependent on the F bit in RIS); 1=LATCH_SW_CLR (Overall fault condition is dependent on the F bit in RIS); 2=LATCH_Z_CLR (Fault condition is latched. Fault condition is cleared on a zero event if the fault input is 0.); 3=LATCH_LD_CLR (Fault condition is latched. Fault condition is cleared on a load event if the fault input is 0.)
    [2] FI — Fault Input Specifies whether the overall fault condition is dependent on the sensed fault pin.
      0=INDEPENDENT (Overall Fault condition is not dependent on sensed input.); 1=DEPENDENT (Overall Fault condition is dependent on sensed input.)
    [0] FIEN — Fault Input Enable This bit enables the input for fault detection.
      0=DISABLED (Fault Input Disabled); 1=ENABLED (Fault Input Enabled)
  0xD4 TIMG8_FIFCTL — Fault input Filter control register
    [4] FILTEN — Filter Enable This bit controls whether the input is filtered by the input filter or bypasses to go directly to the optional pre-scale filter and then to the edge detect.
      0=BYPASS; 1=FILTERED
    [3] CPV — Consecutive Period/Voting Select This bit controls whether the input filter uses a stricter consecutive period count or majority voting.
      0=CONSEC_PER (Consecutive Periods. The input must be at a specific logic level for the period defined by FP before it is passed to the filter output.); 1=VOTING (Voting. The filter ignores one clock of opposite logic over the filter period. I.e. Over FP samples of the input, up to 1 sample may be of an opposite logic value (glitch) without affecting the output)
    [1:0] FP — Filter Period This field specifies the sample period for the input filter. I.e. The input is sampled for FP timer clocks during filtering.
      0=PER_3 (Filter Period 3); 1=PER_5 (Filter Period 5); 2=PER_8 (Filter Period 8)

## TIMG1 — PERIPHERALREGION
Base 0x40086000
Registers as TIMG8 (with TIMG8 read as TIMG1).

## Notices in the file
Copyright (C) 2025 Texas Instruments Incorporated - http://www.ti.com
Redistribution and use in source and binary forms, with or without
modification, are permitted provided that the following conditions
are met:
Redistributions of source code must retain the above copyright
notice, this list of conditions and the following disclaimer.
Redistributions in binary form must reproduce the above copyright
notice, this list of conditions and the following disclaimer in the
documentation and/or other materials provided with the
distribution.
Neither the name of Texas Instruments Incorporated nor the names of
its contributors may be used to endorse or promote products derived
from this software without specific prior written permission.
THIS SOFTWARE IS PROVIDED BY THE COPYRIGHT HOLDERS AND CONTRIBUTORS
"AS IS" AND ANY EXPRESS OR IMPLIED WARRANTIES, INCLUDING, BUT NOT
LIMITED TO, THE IMPLIED WARRANTIES OF MERCHANTABILITY AND FITNESS FOR
A PARTICULAR PURPOSE ARE DISCLAIMED. IN NO EVENT SHALL THE COPYRIGHT
OWNER OR CONTRIBUTORS BE LIABLE FOR ANY DIRECT, INDIRECT, INCIDENTAL,
SPECIAL, EXEMPLARY, OR CONSEQUENTIAL DAMAGES (INCLUDING, BUT NOT
LIMITED TO, PROCUREMENT OF SUBSTITUTE GOODS OR SERVICES; LOSS OF USE,
DATA, OR PROFITS; OR BUSINESS INTERRUPTION) HOWEVER CAUSED AND ON ANY
THEORY OF LIABILITY, WHETHER IN CONTRACT, STRICT LIABILITY, OR TORT
(INCLUDING NEGLIGENCE OR OTHERWISE) ARISING IN ANY WAY OUT OF THE USE
OF THIS SOFTWARE, EVEN IF ADVISED OF THE POSSIBILITY OF SUCH DAMAGE.
